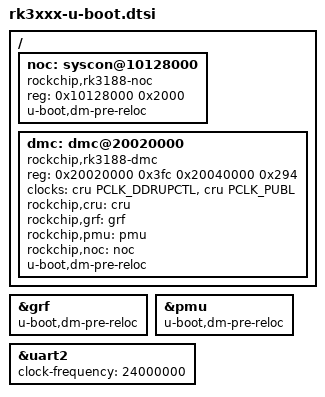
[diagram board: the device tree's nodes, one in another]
// SPDX-License-Identifier: (GPL-2.0+ OR MIT)

/ {
	noc: syscon@10128000 {
		compatible = "rockchip,rk3188-noc", "syscon";
		reg = <0x10128000 0x2000>;
		u-boot,dm-pre-reloc;
	};

	dmc: dmc@20020000 {
		/* unreviewed u-boot-specific binding */
		compatible = "rockchip,rk3188-dmc", "syscon";
		reg = <0x20020000 0x3fc
		       0x20040000 0x294>;
		clocks = <&cru PCLK_DDRUPCTL>, <&cru PCLK_PUBL>;
		clock-names = "pclk_ddrupctl", "pclk_publ";
		rockchip,cru = <&cru>;
		rockchip,grf = <&grf>;
		rockchip,pmu = <&pmu>;
		rockchip,noc = <&noc>;
		u-boot,dm-pre-reloc;
	};
};

&grf {
	u-boot,dm-pre-reloc;
};

&pmu {
	u-boot,dm-pre-reloc;
};

&uart2 {
	clock-frequency = <24000000>;
};
